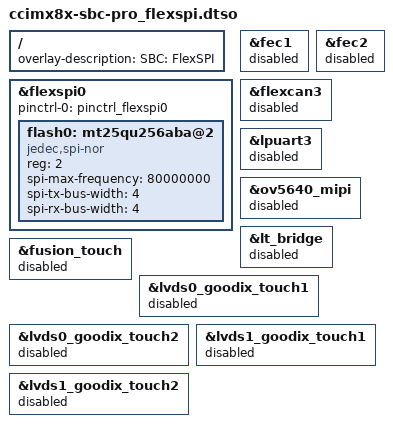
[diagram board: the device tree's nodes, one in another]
/*
 * Copyright 2021 Digi International Inc.
 *
 * Permission to use, copy, modify, and/or distribute this software for any
 * purpose with or without fee is hereby granted, provided that the above
 * copyright notice and this permission notice appear in all copies.
 * THE SOFTWARE IS PROVIDED "AS IS" AND THE AUTHOR DISCLAIMS ALL WARRANTIES
 * WITH REGARD TO THIS SOFTWARE INCLUDING ALL IMPLIED WARRANTIES OF
 * MERCHANTABILITY AND FITNESS. IN NO EVENT SHALL THE AUTHOR BE LIABLE FOR
 * ANY SPECIAL, DIRECT, INDIRECT, OR CONSEQUENTIAL DAMAGES OR ANY DAMAGES
 * WHATSOEVER RESULTING FROM LOSS OF USE, DATA OR PROFITS, WHETHER IN AN
 * ACTION OF CONTRACT, NEGLIGENCE OR OTHER TORTIOUS ACTION, ARISING OUT OF
 * OR IN CONNECTION WITH THE USE OR PERFORMANCE OF THIS SOFTWARE.
 */

/dts-v1/;
/plugin/;

/ {
	fragment@0 {
		target-path = "/";
		__overlay__ {
			overlay-description = "SBC: FlexSPI";
		};
	};

	/* Enable flexspi0 */
	fragment@1 {
		target = <&flexspi0>;
		__overlay__ {
			#address-cells = <1>;
			#size-cells = <0>;
			pinctrl-names = "default";
			pinctrl-0 = <&pinctrl_flexspi0>;
			status = "okay";

			flash0: mt25qu256aba@2 {
				reg = <2>;
				#address-cells = <1>;
				#size-cells = <1>;
				compatible = "jedec,spi-nor";
				spi-max-frequency = <80000000>;
				spi-tx-bus-width = <4>;
				spi-rx-bus-width = <4>;
			};
		};
	};

	/*
	 * The following SBC Pro interfaces need to be disabled due to conflicts
	 * with the QSPI lines.
	 */
	/* Disable fec1 */
	fragment@2 {
		target = <&fec1>;
		__overlay__ {
			status = "disabled";
		};
	};

	/* Disable fec2 */
	fragment@3 {
		target = <&fec2>;
		__overlay__ {
			status = "disabled";
		};
	};

	/* Disable flexcan3 */
	fragment@4 {
		target = <&flexcan3>;
		__overlay__ {
			status = "disabled";
		};
	};

	/* Disable lpuart3 */
	fragment@5 {
		target = <&lpuart3>;
		__overlay__ {
			status = "disabled";
		};
	};

	/* Disable ov5640_mipi */
	fragment@6 {
		target = <&ov5640_mipi>;
		__overlay__ {
			status = "disabled";
		};
	};

	/* Disable lt_bridge */
	fragment@7 {
		target = <&lt_bridge>;
		__overlay__ {
			status = "disabled";
		};
	};

	/* Disable fusion_touch */
	fragment@8 {
		target = <&fusion_touch>;
		__overlay__ {
			status = "disabled";
		};
	};

	/* Disable lvds0_goodix_touch1 */
	fragment@9 {
		target = <&lvds0_goodix_touch1>;
		__overlay__ {
			status = "disabled";
		};
	};

	/* Disable lvds0_goodix_touch2 */
	fragment@10 {
		target = <&lvds0_goodix_touch2>;
		__overlay__ {
			status = "disabled";
		};
	};

	/* Disable lvds1_goodix_touch1 */
	fragment@11 {
		target = <&lvds1_goodix_touch1>;
		__overlay__ {
			status = "disabled";
		};
	};

	/* Disable lvds1_goodix_touch2 */
	fragment@12 {
		target = <&lvds1_goodix_touch2>;
		__overlay__ {
			status = "disabled";
		};
	};
};
